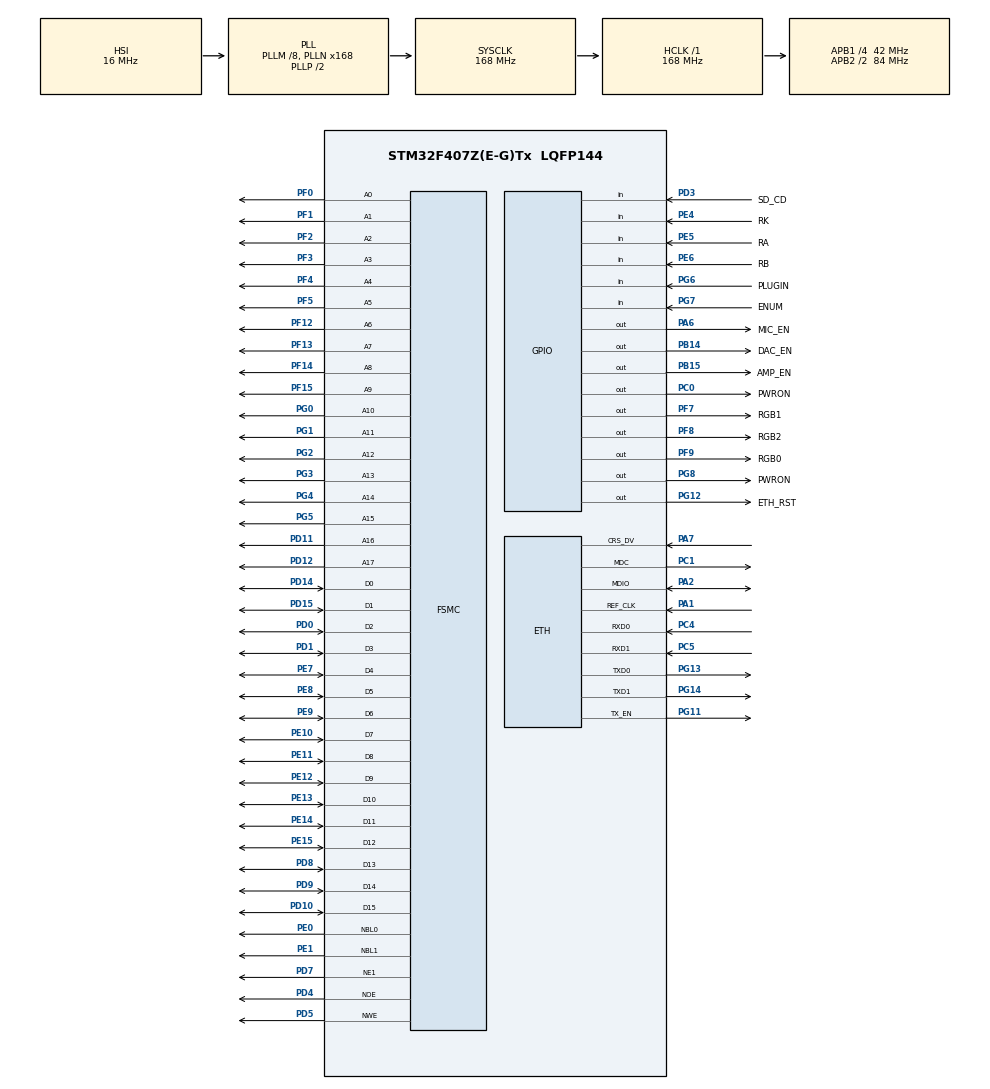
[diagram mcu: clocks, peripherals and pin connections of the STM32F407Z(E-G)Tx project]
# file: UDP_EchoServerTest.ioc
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ETH.AutoNegotiation=ETH_AUTONEGOTIATION_ENABLE
ETH.MediaInterface=ETH_MEDIA_INTERFACE_RMII
ETH.PHY_AUTONEGO_COMPLETE=0x0020
ETH.PHY_DUPLEX_STATUS=0x0200
ETH.PHY_Name_RMII=userPHY
ETH.PHY_SPEED_STATUS=0x0400
ETH.PhyAddress=1
FSMC.WriteOperation1=FSMC_WRITE_OPERATION_ENABLE
LWIP.GATEWAY_ADDRESS=192.168.001.001
LWIP.IP_ADDRESS=192.168.001.201
LWIP.LWIP_DHCP=0
LWIP.NETMASK_ADDRESS=255.255.255.000
LWIP.Version=v2.0.0_Cube
Mcu.Family=STM32F4
Mcu.Name=STM32F407Z(E-G)Tx
Mcu.Package=LQFP144
NVIC.ETH_IRQn=true\:1\:0\:true\:false\:true\:true
NVIC.PriorityGroup=NVIC_PRIORITYGROUP_2
PA0-WKUP.Mode=SYS_WakeUp0
PA0-WKUP.Signal=SYS_WKUP
PA1.Mode=RMII
PA1.Signal=ETH_REF_CLK
PA13.Mode=Serial_Wire
PA13.Signal=SYS_JTMS-SWDIO
PA14.Mode=Serial_Wire
PA14.Signal=SYS_JTCK-SWCLK
PA2.Mode=RMII
PA2.Signal=ETH_MDIO
PA6.GPIO_Label=MIC_EN
PA6.Signal=GPIO_Output
PA7.Mode=RMII
PA7.Signal=ETH_CRS_DV
PB14.GPIO_Label=DAC_EN
PB14.Signal=GPIO_Output
PB15.GPIO_Label=AMP_EN
PB15.Signal=GPIO_Output
PC0.GPIO_Label=PWRON
PC0.Signal=GPIO_Output
PC1.Mode=RMII
PC1.Signal=ETH_MDC
PC14-OSC32_IN.Mode=LSE-External-Oscillator
PC14-OSC32_IN.Signal=RCC_OSC32_IN
PC15-OSC32_OUT.Mode=LSE-External-Oscillator
PC15-OSC32_OUT.Signal=RCC_OSC32_OUT
PC4.Mode=RMII
PC4.Signal=ETH_RXD0
PC5.Mode=RMII
PC5.Signal=ETH_RXD1
PD0.Signal=FSMC_D2_DA2
PD1.Signal=FSMC_D3_DA3
PD10.Signal=FSMC_D15_DA15
PD11.Signal=FSMC_A16_CLE
PD12.Signal=FSMC_A17_ALE
PD14.Signal=FSMC_D0_DA0
PD15.Signal=FSMC_D1_DA1
PD3.GPIO_Label=SD_CD
PD3.Signal=GPIO_Input
PD4.Signal=FSMC_NOE
PD5.Signal=FSMC_NWE
PD7.Mode=NorPsramChipSelect1_1
PD7.Signal=FSMC_NE1
PD8.Signal=FSMC_D13_DA13
PD9.Signal=FSMC_D14_DA14
PE0.Signal=FSMC_NBL0
PE1.Signal=FSMC_NBL1
PE10.Signal=FSMC_D7_DA7
PE11.Signal=FSMC_D8_DA8
PE12.Signal=FSMC_D9_DA9
PE13.Signal=FSMC_D10_DA10
PE14.Signal=FSMC_D11_DA11
PE15.Signal=FSMC_D12_DA12
PE4.GPIO_Label=RK
PE4.Signal=GPIO_Input
PE5.GPIO_Label=RA
PE5.Signal=GPIO_Input
PE6.GPIO_Label=RB
PE6.Signal=GPIO_Input
PE7.Signal=FSMC_D4_DA4
PE8.Signal=FSMC_D5_DA5
PE9.Signal=FSMC_D6_DA6
PF0.Signal=FSMC_A0
PF1.Signal=FSMC_A1
PF12.Signal=FSMC_A6
PF13.Signal=FSMC_A7
PF14.Signal=FSMC_A8
PF15.Signal=FSMC_A9
PF2.Signal=FSMC_A2
PF3.Signal=FSMC_A3
PF4.Signal=FSMC_A4
PF5.Signal=FSMC_A5
PF7.GPIO_Label=RGB1
PF7.Signal=GPIO_Output
PF8.GPIO_Label=RGB2
PF8.Signal=GPIO_Output
PF9.GPIO_Label=RGB0
PF9.Signal=GPIO_Output
PG0.Signal=FSMC_A10
PG1.Signal=FSMC_A11
PG11.Mode=RMII
PG11.Signal=ETH_TX_EN
PG12.GPIO_Label=ETH_RST
PG12.PinState=GPIO_PIN_SET
PG12.Signal=GPIO_Output
PG13.Mode=RMII
PG13.Signal=ETH_TXD0
PG14.Mode=RMII
PG14.Signal=ETH_TXD1
PG2.Signal=FSMC_A12
PG3.Signal=FSMC_A13
PG4.Signal=FSMC_A14
PG5.Signal=FSMC_A15
PG6.GPIO_Label=PLUGIN
PG6.Signal=GPIO_Input
PG7.GPIO_Label=ENUM
PG7.Signal=GPIO_Input
PG8.GPIO_Label=PWRON
PG8.Signal=GPIO_Output
PH0-OSC_IN.Mode=HSE-External-Oscillator
PH0-OSC_IN.Signal=RCC_OSC_IN
PH1-OSC_OUT.Mode=HSE-External-Oscillator
PH1-OSC_OUT.Signal=RCC_OSC_OUT
ProjectManager.HeapSize=0x200
ProjectManager.StackSize=0x400
ProjectManager.TargetToolchain=MDK-ARM V5
RCC.48MHZClocksFreq_Value=84000000
RCC.AHBFreq_Value=168000000
RCC.APB1CLKDivider=RCC_HCLK_DIV4
RCC.APB1Freq_Value=42000000
RCC.APB1TimFreq_Value=84000000
RCC.APB2CLKDivider=RCC_HCLK_DIV2
RCC.APB2Freq_Value=84000000
RCC.APB2TimFreq_Value=168000000
RCC.CortexFreq_Value=21000000
RCC.Cortex_Div=SYSTICK_CLKSOURCE_HCLK_DIV8
RCC.HCLKFreq_Value=168000000
RCC.HSE_VALUE=25000000
RCC.HSI_VALUE=16000000
RCC.PLLI2SN=100
RCC.PLLM=8
RCC.PLLN=168
RCC.PLLQ=7
RCC.RCC_RTC_Clock_SourceVirtual=RCC_RTCCLKSOURCE_LSE
RCC.SYSCLKFreq_VALUE=168000000
RCC.SYSCLKSource=RCC_SYSCLKSOURCE_PLLCLK
RCC.VCOOutputFreq_Value=336000000
SH.FSMC_A0.0=FSMC_A0,18b-a1
SH.FSMC_A1.0=FSMC_A1,18b-a1
SH.FSMC_A10.0=FSMC_A10,18b-a1
SH.FSMC_A11.0=FSMC_A11,18b-a1
SH.FSMC_A12.0=FSMC_A12,18b-a1
SH.FSMC_A13.0=FSMC_A13,18b-a1
SH.FSMC_A14.0=FSMC_A14,18b-a1
SH.FSMC_A15.0=FSMC_A15,18b-a1
SH.FSMC_A16_CLE.0=FSMC_A16,18b-a1
SH.FSMC_A17_ALE.0=FSMC_A17,18b-a1
SH.FSMC_A2.0=FSMC_A2,18b-a1
SH.FSMC_A3.0=FSMC_A3,18b-a1
SH.FSMC_A4.0=FSMC_A4,18b-a1
SH.FSMC_A5.0=FSMC_A5,18b-a1
SH.FSMC_A6.0=FSMC_A6,18b-a1
SH.FSMC_A7.0=FSMC_A7,18b-a1
SH.FSMC_A8.0=FSMC_A8,18b-a1
SH.FSMC_A9.0=FSMC_A9,18b-a1
SH.FSMC_D0_DA0.0=FSMC_D0,16b-d1
SH.FSMC_D10_DA10.0=FSMC_D10,16b-d1
SH.FSMC_D11_DA11.0=FSMC_D11,16b-d1
SH.FSMC_D12_DA12.0=FSMC_D12,16b-d1
SH.FSMC_D13_DA13.0=FSMC_D13,16b-d1
SH.FSMC_D14_DA14.0=FSMC_D14,16b-d1
SH.FSMC_D15_DA15.0=FSMC_D15,16b-d1
SH.FSMC_D1_DA1.0=FSMC_D1,16b-d1
SH.FSMC_D2_DA2.0=FSMC_D2,16b-d1
SH.FSMC_D3_DA3.0=FSMC_D3,16b-d1
SH.FSMC_D4_DA4.0=FSMC_D4,16b-d1
SH.FSMC_D5_DA5.0=FSMC_D5,16b-d1
SH.FSMC_D6_DA6.0=FSMC_D6,16b-d1
SH.FSMC_D7_DA7.0=FSMC_D7,16b-d1
SH.FSMC_D8_DA8.0=FSMC_D8,16b-d1
SH.FSMC_D9_DA9.0=FSMC_D9,16b-d1
SH.FSMC_NBL0.0=FSMC_NBL0,2ByteEnable1
SH.FSMC_NBL1.0=FSMC_NBL1,2ByteEnable1
SH.FSMC_NOE.0=FSMC_NOE,Sram1
SH.FSMC_NWE.0=FSMC_NWE,Sram1
VP_LWIP_VS_Enabled.Mode=Enabled
VP_RTC_VS_RTC_Activate.Mode=RTC_Enabled
board=UDP_EchoServerTest

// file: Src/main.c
/**
  ******************************************************************************
  * File Name          : main.c
  * Description        : Main program body
  ******************************************************************************
  * This notice applies to any and all portions of this file
  * that are not between comment pairs USER CODE BEGIN and
  * USER CODE END. Other portions of this file, whether
  * inserted by the user or by software development tools
  * are owned by their respective copyright owners.
  *
  * Copyright (c) 2017 STMicroelectronics International N.V.
  * All rights reserved.
  *
  * Redistribution and use in source and binary forms, with or without
  * modification, are permitted, provided that the following conditions are met:
  *
  * 1. Redistribution of source code must retain the above copyright notice,
  *    this list of conditions and the following disclaimer.
  * 2. Redistributions in binary form must reproduce the above copyright notice,
  *    this list of conditions and the following disclaimer in the documentation
  *    and/or other materials provided with the distribution.
  * 3. Neither the name of STMicroelectronics nor the names of other
  *    contributors to this software may be used to endorse or promote products
  *    derived from this software without specific written permission.
  * 4. This software, including modifications and/or derivative works of this
  *    software, must execute solely and exclusively on microcontroller or
  *    microprocessor devices manufactured by or for STMicroelectronics.
  * 5. Redistribution and use of this software other than as permitted under
  *    this license is void and will automatically terminate your rights under
  *    this license.
  *
  * THIS SOFTWARE IS PROVIDED BY STMICROELECTRONICS AND CONTRIBUTORS "AS IS"
  * AND ANY EXPRESS, IMPLIED OR STATUTORY WARRANTIES, INCLUDING, BUT NOT
  * LIMITED TO, THE IMPLIED WARRANTIES OF MERCHANTABILITY, FITNESS FOR A
  * PARTICULAR PURPOSE AND NON-INFRINGEMENT OF THIRD PARTY INTELLECTUAL PROPERTY
  * RIGHTS ARE DISCLAIMED TO THE FULLEST EXTENT PERMITTED BY LAW. IN NO EVENT
  * SHALL STMICROELECTRONICS OR CONTRIBUTORS BE LIABLE FOR ANY DIRECT, INDIRECT,
  * INCIDENTAL, SPECIAL, EXEMPLARY, OR CONSEQUENTIAL DAMAGES (INCLUDING, BUT NOT
  * LIMITED TO, PROCUREMENT OF SUBSTITUTE GOODS OR SERVICES; LOSS OF USE, DATA,
  * OR PROFITS; OR BUSINESS INTERRUPTION) HOWEVER CAUSED AND ON ANY THEORY OF
  * LIABILITY, WHETHER IN CONTRACT, STRICT LIABILITY, OR TORT (INCLUDING
  * NEGLIGENCE OR OTHERWISE) ARISING IN ANY WAY OUT OF THE USE OF THIS SOFTWARE,
  * EVEN IF ADVISED OF THE POSSIBILITY OF SUCH DAMAGE.
  *
  ******************************************************************************
  */
#include "main.h"
#include "stm32f4xx_hal.h"
#include "lwip.h"

/* USER CODE BEGIN Includes */
#include "udp_echoserver.h"
/* USER CODE END Includes */

RTC_HandleTypeDef hrtc;

SRAM_HandleTypeDef hsram1;

/* USER CODE BEGIN PV */
/* Private variables ---------------------------------------------------------*/

/* USER CODE END PV */

void SystemClock_Config(void);
static void MX_GPIO_Init(void);
static void MX_FSMC_Init(void);
static void MX_RTC_Init(void);

/* USER CODE BEGIN PFP */
/* Private function prototypes -----------------------------------------------*/

/* USER CODE END PFP */

int main(void)
{

  /* MCU Configuration----------------------------------------------------------*/

  /* Reset of all peripherals, Initializes the Flash interface and the Systick. */
  HAL_Init();

  /* Configure the system clock */
  SystemClock_Config();

  /* Initialize all configured peripherals */
  MX_GPIO_Init();
  MX_FSMC_Init();
  MX_RTC_Init();
  MX_LWIP_Init();

  /* USER CODE BEGIN 2 */
   udp_echoserver_init();
  /* USER CODE END 2 */

  /* Infinite loop */
  while (1)
  {

  /* USER CODE BEGIN 3 */
   MX_LWIP_Process();
  }
  /* USER CODE END 3 */

}

/** System Clock Configuration
*/
void SystemClock_Config(void)
{

  RCC_OscInitTypeDef RCC_OscInitStruct;
  RCC_ClkInitTypeDef RCC_ClkInitStruct;
  RCC_PeriphCLKInitTypeDef PeriphClkInitStruct;

    /**Configure the main internal regulator output voltage
    */
  __HAL_RCC_PWR_CLK_ENABLE();

  __HAL_PWR_VOLTAGESCALING_CONFIG(PWR_REGULATOR_VOLTAGE_SCALE1);

    /**Initializes the CPU, AHB and APB busses clocks
    */
  RCC_OscInitStruct.OscillatorType = RCC_OSCILLATORTYPE_HSI|RCC_OSCILLATORTYPE_LSE;
  RCC_OscInitStruct.LSEState = RCC_LSE_ON;
  RCC_OscInitStruct.HSIState = RCC_HSI_ON;
  RCC_OscInitStruct.HSICalibrationValue = 16;
  RCC_OscInitStruct.PLL.PLLState = RCC_PLL_ON;
  RCC_OscInitStruct.PLL.PLLSource = RCC_PLLSOURCE_HSI;
  RCC_OscInitStruct.PLL.PLLM = 8;
  RCC_OscInitStruct.PLL.PLLN = 168;
  RCC_OscInitStruct.PLL.PLLP = RCC_PLLP_DIV2;
  RCC_OscInitStruct.PLL.PLLQ = 7;
  if (HAL_RCC_OscConfig(&RCC_OscInitStruct) != HAL_OK)
  {
    _Error_Handler(__FILE__, __LINE__);
  }

    /**Initializes the CPU, AHB and APB busses clocks
    */
  RCC_ClkInitStruct.ClockType = RCC_CLOCKTYPE_HCLK|RCC_CLOCKTYPE_SYSCLK
                              |RCC_CLOCKTYPE_PCLK1|RCC_CLOCKTYPE_PCLK2;
  RCC_ClkInitStruct.SYSCLKSource = RCC_SYSCLKSOURCE_PLLCLK;
  RCC_ClkInitStruct.AHBCLKDivider = RCC_SYSCLK_DIV1;
  RCC_ClkInitStruct.APB1CLKDivider = RCC_HCLK_DIV4;
  RCC_ClkInitStruct.APB2CLKDivider = RCC_HCLK_DIV2;

  if (HAL_RCC_ClockConfig(&RCC_ClkInitStruct, FLASH_LATENCY_5) != HAL_OK)
  {
    _Error_Handler(__FILE__, __LINE__);
  }

  PeriphClkInitStruct.PeriphClockSelection = RCC_PERIPHCLK_RTC;
  PeriphClkInitStruct.RTCClockSelection = RCC_RTCCLKSOURCE_LSE;
  if (HAL_RCCEx_PeriphCLKConfig(&PeriphClkInitStruct) != HAL_OK)
  {
    _Error_Handler(__FILE__, __LINE__);
  }

    /**Configure the Systick interrupt time
    */
  HAL_SYSTICK_Config(HAL_RCC_GetHCLKFreq()/8000);

    /**Configure the Systick
    */
  HAL_SYSTICK_CLKSourceConfig(SYSTICK_CLKSOURCE_HCLK_DIV8);

  /* SysTick_IRQn interrupt configuration */
  HAL_NVIC_SetPriority(SysTick_IRQn, 0, 0);
}

/* RTC init function */
static void MX_RTC_Init(void)
{

    /**Initialize RTC Only
    */
  hrtc.Instance = RTC;
  hrtc.Init.HourFormat = RTC_HOURFORMAT_24;
  hrtc.Init.AsynchPrediv = 127;
  hrtc.Init.SynchPrediv = 255;
  hrtc.Init.OutPut = RTC_OUTPUT_DISABLE;
  hrtc.Init.OutPutPolarity = RTC_OUTPUT_POLARITY_HIGH;
  hrtc.Init.OutPutType = RTC_OUTPUT_TYPE_OPENDRAIN;
  if (HAL_RTC_Init(&hrtc) != HAL_OK)
  {
    _Error_Handler(__FILE__, __LINE__);
  }

}

/** Configure pins as
        * Analog
        * Input
        * Output
        * EVENT_OUT
        * EXTI
*/
static void MX_GPIO_Init(void)
{

  GPIO_InitTypeDef GPIO_InitStruct;

  /* GPIO Ports Clock Enable */
  __HAL_RCC_GPIOE_CLK_ENABLE();
  __HAL_RCC_GPIOC_CLK_ENABLE();
  __HAL_RCC_GPIOF_CLK_ENABLE();
  __HAL_RCC_GPIOH_CLK_ENABLE();
  __HAL_RCC_GPIOA_CLK_ENABLE();
  __HAL_RCC_GPIOG_CLK_ENABLE();
  __HAL_RCC_GPIOB_CLK_ENABLE();
  __HAL_RCC_GPIOD_CLK_ENABLE();

  /*Configure GPIO pin Output Level */
  HAL_GPIO_WritePin(GPIOF, RGB1_Pin|RGB2_Pin|RGB0_Pin, GPIO_PIN_RESET);

  /*Configure GPIO pin Output Level */
  HAL_GPIO_WritePin(PWRON_GPIO_Port, PWRON_Pin, GPIO_PIN_RESET);

  /*Configure GPIO pin Output Level */
  HAL_GPIO_WritePin(MIC_EN_GPIO_Port, MIC_EN_Pin, GPIO_PIN_RESET);

  /*Configure GPIO pin Output Level */
  HAL_GPIO_WritePin(GPIOB, DAC_EN_Pin|AMP_EN_Pin, GPIO_PIN_RESET);

  /*Configure GPIO pin Output Level */
  HAL_GPIO_WritePin(PWRONG8_GPIO_Port, PWRONG8_Pin, GPIO_PIN_RESET);

  /*Configure GPIO pin Output Level */
  HAL_GPIO_WritePin(ETH_RST_GPIO_Port, ETH_RST_Pin, GPIO_PIN_SET);

  /*Configure GPIO pins : RK_Pin RA_Pin RB_Pin */
  GPIO_InitStruct.Pin = RK_Pin|RA_Pin|RB_Pin;
  GPIO_InitStruct.Mode = GPIO_MODE_INPUT;
  GPIO_InitStruct.Pull = GPIO_NOPULL;
  HAL_GPIO_Init(GPIOE, &GPIO_InitStruct);

  /*Configure GPIO pins : RGB1_Pin RGB2_Pin RGB0_Pin */
  GPIO_InitStruct.Pin = RGB1_Pin|RGB2_Pin|RGB0_Pin;
  GPIO_InitStruct.Mode = GPIO_MODE_OUTPUT_PP;
  GPIO_InitStruct.Pull = GPIO_NOPULL;
  GPIO_InitStruct.Speed = GPIO_SPEED_FREQ_LOW;
  HAL_GPIO_Init(GPIOF, &GPIO_InitStruct);

  /*Configure GPIO pin : PWRON_Pin */
  GPIO_InitStruct.Pin = PWRON_Pin;
  GPIO_InitStruct.Mode = GPIO_MODE_OUTPUT_PP;
  GPIO_InitStruct.Pull = GPIO_NOPULL;
  GPIO_InitStruct.Speed = GPIO_SPEED_FREQ_LOW;
  HAL_GPIO_Init(PWRON_GPIO_Port, &GPIO_InitStruct);

  /*Configure GPIO pin : MIC_EN_Pin */
  GPIO_InitStruct.Pin = MIC_EN_Pin;
  GPIO_InitStruct.Mode = GPIO_MODE_OUTPUT_PP;
  GPIO_InitStruct.Pull = GPIO_NOPULL;
  GPIO_InitStruct.Speed = GPIO_SPEED_FREQ_LOW;
  HAL_GPIO_Init(MIC_EN_GPIO_Port, &GPIO_InitStruct);

  /*Configure GPIO pins : DAC_EN_Pin AMP_EN_Pin */
  GPIO_InitStruct.Pin = DAC_EN_Pin|AMP_EN_Pin;
  GPIO_InitStruct.Mode = GPIO_MODE_OUTPUT_PP;
  GPIO_InitStruct.Pull = GPIO_NOPULL;
  GPIO_InitStruct.Speed = GPIO_SPEED_FREQ_LOW;
  HAL_GPIO_Init(GPIOB, &GPIO_InitStruct);

  /*Configure GPIO pins : PLUGIN_Pin ENUM_Pin */
  GPIO_InitStruct.Pin = PLUGIN_Pin|ENUM_Pin;
  GPIO_InitStruct.Mode = GPIO_MODE_INPUT;
  GPIO_InitStruct.Pull = GPIO_NOPULL;
  HAL_GPIO_Init(GPIOG, &GPIO_InitStruct);

  /*Configure GPIO pins : PWRONG8_Pin ETH_RST_Pin */
  GPIO_InitStruct.Pin = PWRONG8_Pin|ETH_RST_Pin;
  GPIO_InitStruct.Mode = GPIO_MODE_OUTPUT_PP;
  GPIO_InitStruct.Pull = GPIO_NOPULL;
  GPIO_InitStruct.Speed = GPIO_SPEED_FREQ_LOW;
  HAL_GPIO_Init(GPIOG, &GPIO_InitStruct);

  /*Configure GPIO pin : SD_CD_Pin */
  GPIO_InitStruct.Pin = SD_CD_Pin;
  GPIO_InitStruct.Mode = GPIO_MODE_INPUT;
  GPIO_InitStruct.Pull = GPIO_NOPULL;
  HAL_GPIO_Init(SD_CD_GPIO_Port, &GPIO_InitStruct);

}

/* FSMC initialization function */
static void MX_FSMC_Init(void)
{
  FSMC_NORSRAM_TimingTypeDef Timing;

  /** Perform the SRAM1 memory initialization sequence
  */
  hsram1.Instance = FSMC_NORSRAM_DEVICE;
  hsram1.Extended = FSMC_NORSRAM_EXTENDED_DEVICE;
  /* hsram1.Init */
  hsram1.Init.NSBank = FSMC_NORSRAM_BANK1;
  hsram1.Init.DataAddressMux = FSMC_DATA_ADDRESS_MUX_DISABLE;
  hsram1.Init.MemoryType = FSMC_MEMORY_TYPE_SRAM;
  hsram1.Init.MemoryDataWidth = FSMC_NORSRAM_MEM_BUS_WIDTH_16;
  hsram1.Init.BurstAccessMode = FSMC_BURST_ACCESS_MODE_DISABLE;
  hsram1.Init.WaitSignalPolarity = FSMC_WAIT_SIGNAL_POLARITY_LOW;
  hsram1.Init.WrapMode = FSMC_WRAP_MODE_DISABLE;
  hsram1.Init.WaitSignalActive = FSMC_WAIT_TIMING_BEFORE_WS;
  hsram1.Init.WriteOperation = FSMC_WRITE_OPERATION_ENABLE;
  hsram1.Init.WaitSignal = FSMC_WAIT_SIGNAL_DISABLE;
  hsram1.Init.ExtendedMode = FSMC_EXTENDED_MODE_DISABLE;
  hsram1.Init.AsynchronousWait = FSMC_ASYNCHRONOUS_WAIT_DISABLE;
  hsram1.Init.WriteBurst = FSMC_WRITE_BURST_DISABLE;
  hsram1.Init.PageSize = FSMC_PAGE_SIZE_NONE;
  /* Timing */
  Timing.AddressSetupTime = 15;
  Timing.AddressHoldTime = 15;
  Timing.DataSetupTime = 255;
  Timing.BusTurnAroundDuration = 15;
  Timing.CLKDivision = 16;
  Timing.DataLatency = 17;
  Timing.AccessMode = FSMC_ACCESS_MODE_A;
  /* ExtTiming */

  if (HAL_SRAM_Init(&hsram1, &Timing, NULL) != HAL_OK)
  {
    _Error_Handler(__FILE__, __LINE__);
  }

}

void _Error_Handler(char * file, int line)
{
  while(1)
  {
  }
}

/************************ (C) COPYRIGHT STMicroelectronics *****END OF FILE****/
